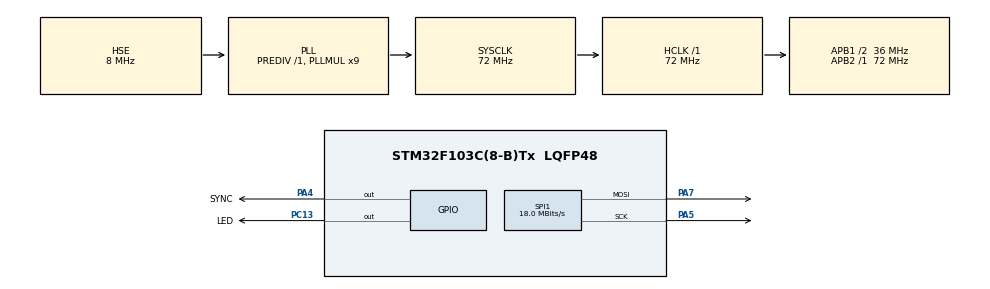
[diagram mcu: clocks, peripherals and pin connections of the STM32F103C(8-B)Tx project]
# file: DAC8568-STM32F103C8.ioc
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Mcu.Family=STM32F1
Mcu.Name=STM32F103C(8-B)Tx
Mcu.Package=LQFP48
NVIC.PriorityGroup=NVIC_PRIORITYGROUP_4
PA13.Mode=Serial_Wire
PA13.Signal=SYS_JTMS-SWDIO
PA14.Mode=Serial_Wire
PA14.Signal=SYS_JTCK-SWCLK
PA4.GPIO_Label=SYNC
PA4.GPIO_Speed=GPIO_SPEED_FREQ_HIGH
PA4.Signal=GPIO_Output
PA5.Mode=TX_Only_Simplex_Unidirect_Master
PA5.Signal=SPI1_SCK
PA7.Mode=TX_Only_Simplex_Unidirect_Master
PA7.Signal=SPI1_MOSI
PC13-TAMPER-RTC.GPIO_Label=LED
PC13-TAMPER-RTC.GPIO_Speed=GPIO_SPEED_FREQ_HIGH
PC13-TAMPER-RTC.Signal=GPIO_Output
PD0-OSC_IN.Mode=HSE-External-Oscillator
PD0-OSC_IN.Signal=RCC_OSC_IN
PD1-OSC_OUT.Mode=HSE-External-Oscillator
PD1-OSC_OUT.Signal=RCC_OSC_OUT
ProjectManager.HeapSize=0x200
ProjectManager.StackSize=0x400
ProjectManager.TargetToolchain=STM32CubeIDE
RCC.AHBFreq_Value=72000000
RCC.APB1CLKDivider=RCC_HCLK_DIV2
RCC.APB1Freq_Value=36000000
RCC.APB1TimFreq_Value=72000000
RCC.APB2Freq_Value=72000000
RCC.APB2TimFreq_Value=72000000
RCC.HCLKFreq_Value=72000000
RCC.PLLMUL=RCC_PLL_MUL9
RCC.PLLSourceVirtual=RCC_PLLSOURCE_HSE
RCC.SYSCLKFreq_VALUE=72000000
RCC.SYSCLKSource=RCC_SYSCLKSOURCE_PLLCLK
RCC.USBFreq_Value=72000000
SPI1.BaudRatePrescaler=SPI_BAUDRATEPRESCALER_4
SPI1.CLKPolarity=SPI_POLARITY_HIGH
SPI1.CalculateBaudRate=18.0 MBits/s
SPI1.Direction=SPI_DIRECTION_2LINES
SPI1.FirstBit=SPI_FIRSTBIT_MSB
SPI1.Mode=SPI_MODE_MASTER
SPI1.VirtualType=VM_MASTER
board=custom

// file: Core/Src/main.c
/* USER CODE BEGIN Header */
/**
 ******************************************************************************
 * @file           : main.c
 * @brief          : Main program body
 ******************************************************************************
 * @attention
 *
 * Copyright (c) 2025 STMicroelectronics.
 * All rights reserved.
 *
 * This software is licensed under terms that can be found in the LICENSE file
 * in the root directory of this software component.
 * If no LICENSE file comes with this software, it is provided AS-IS.
 *
 ******************************************************************************
 */
/*
 * DAC8568/DAC8168/DAC8568 驱动程序
 * 作者: 雪豹
 */
/*
 * 注释在DAC8568.h中
 * SPI 外设配置说明 (针对 DAC8568)
 * ----------------------------------------------------------------
 * 参数要求（参考数据手册第7-8页时序图和第6页电气特性）：
 * 1. 模式: 全双工主模式 (DAC8568 为从设备)
 * 2. 数据大小: 8位 (需手动组合为24/32位帧)
 * 3. 时钟极性 (CPOL): 高电平空闲 (CPOL=high)
 * 4. 时钟相位 (CPHA): 数据在第一个边沿采样 (CPHA=0)
 * 5. 传输顺序: MSB 高位在前 (强制要求)
 * 6. 波特率: ≤50MHz (建议根据主频选择分频器)
 * 7. 硬件NSS: 禁用 (使用独立GPIO控制SYNC引脚)
 *
 * CubeMX 具体设置步骤：
 * 1. Connectivity → SPIx → Mode = "Full-Duplex Master"
 * 2. Parameter Settings →
 *    - Data Size = 8 Bits
 *    - First Bit = MSB First
 *    - Clock Polarity = High  注意这个
 *    - Clock Phase = 1 Edge
 *    - Baud Rate Prescaler = 分频值 (如 2/4/8，确保 SCLK ≤50MHz)
 * 3. GPIO Settings →
 *    - 配置 SYNC 引脚为 GPIO_Output (初始化高电平)
 *    - MOSI/SCK 自动分配，模式为 Alternate Function Push-Pull
 */
/*
 * DAC8568 硬件连接说明：
 * ----------------------------------------------------------------
 * DAC8568引脚 | STM32引脚       | 备注
 * -----------|----------------|-----------------------------------
 * DIN        | SPIx_MOSI      | 主设备输出，直连无需上拉
 * SCLK       | SPIx_SCK       | 保持短走线，减少干扰
 * SYNC       | 任意GPIO (如PA4)| 需配置为输出模式，传输前拉低
 * VDD        | 3.3V           | 电源需并联100nF去耦电容
 * GND        | GND            | 共地
 */

/* USER CODE END Header */
#include "main.h"
#include "spi.h"
#include "gpio.h"

/* USER CODE BEGIN Includes */
#include "dac8568.h" // 包含DAC8568的头文件
/* USER CODE END Includes */

void SystemClock_Config(void);

int main(void)
{

  /* MCU Configuration--------------------------------------------------------*/

  /* Reset of all peripherals, Initializes the Flash interface and the Systick. */
  HAL_Init();

  /* Configure the system clock */
  SystemClock_Config();

  /* Initialize all configured peripherals */
  MX_GPIO_Init();
  MX_SPI1_Init();
  /* USER CODE BEGIN 2 */
  // 初始化DAC8568 (SYNC连接到PA4)
  DAC8568_Init(&hspi1, SYNC_GPIO_Port, SYNC_Pin);
  HAL_Delay(10);
  DAC8568_EnableStaticInternalRef(); // 启用静态内部参考(2.5V)
  // DAC8568_DisableStaticInternalRef(); // 禁用静态内部参考(2.5V)

  /* USER CODE END 2 */

  /* Infinite loop */
  /* USER CODE BEGIN WHILE */
  while (1)
  {

    for (int i = 65535; i >= 0; i = i - 4096) // 从65535到0，步长4096
    {
      HAL_GPIO_TogglePin(LED_GPIO_Port, LED_Pin);     // 翻转LED引脚的状态
      DAC8568_WriteAndUpdate(BROADCAST, (uint16_t)i); // 写入并更新所有通道的值 (强制类型转换为uint16_t)
      // DAC8568_WriteAndUpdate(CHANNEL_A, (uint16_t)i); // 写入并更新通道A的值 (强制类型转换为uint16_t)
      // DAC8568_WriteAndUpdate(CHANNEL_B, (uint16_t)i); // 写入并更新通道B的值 (强制类型转换为uint16_t)
      float voltage = 2.5 * 2 * i / 65536;         // 计算电压值 (假设Vref=2.5V，16位分辨率)
      HAL_Delay(2000);                             // 稍微缩短延时以便观察变化，可根据需要调整
    }

    /* USER CODE END WHILE */

  }
}

void SystemClock_Config(void)
{
  RCC_OscInitTypeDef RCC_OscInitStruct = {0};
  RCC_ClkInitTypeDef RCC_ClkInitStruct = {0};

  /** Initializes the RCC Oscillators according to the specified parameters
   * in the RCC_OscInitTypeDef structure.
   */
  RCC_OscInitStruct.OscillatorType = RCC_OSCILLATORTYPE_HSE;
  RCC_OscInitStruct.HSEState = RCC_HSE_ON;
  RCC_OscInitStruct.HSEPredivValue = RCC_HSE_PREDIV_DIV1;
  RCC_OscInitStruct.HSIState = RCC_HSI_ON;
  RCC_OscInitStruct.PLL.PLLState = RCC_PLL_ON;
  RCC_OscInitStruct.PLL.PLLSource = RCC_PLLSOURCE_HSE;
  RCC_OscInitStruct.PLL.PLLMUL = RCC_PLL_MUL9;
  if (HAL_RCC_OscConfig(&RCC_OscInitStruct) != HAL_OK)
  {
    Error_Handler();
  }

  /** Initializes the CPU, AHB and APB buses clocks
   */
  RCC_ClkInitStruct.ClockType = RCC_CLOCKTYPE_HCLK | RCC_CLOCKTYPE_SYSCLK | RCC_CLOCKTYPE_PCLK1 | RCC_CLOCKTYPE_PCLK2;
  RCC_ClkInitStruct.SYSCLKSource = RCC_SYSCLKSOURCE_PLLCLK;
  RCC_ClkInitStruct.AHBCLKDivider = RCC_SYSCLK_DIV1;
  RCC_ClkInitStruct.APB1CLKDivider = RCC_HCLK_DIV2;
  RCC_ClkInitStruct.APB2CLKDivider = RCC_HCLK_DIV1;

  if (HAL_RCC_ClockConfig(&RCC_ClkInitStruct, FLASH_LATENCY_2) != HAL_OK)
  {
    Error_Handler();
  }
}

void Error_Handler(void)
{
  __disable_irq();
  while (1)
  {
  }
}
